# GPMC register map
Vendor: Texas Instruments
Peripheral module from a debugger description file (folder omap5430_ES2_PUBLIC).
Registers are 32-bit, read-write, reset 0x0 unless marked. A register's access mark holds for its fields unless they carry their own. Offsets are as the file gives them; lines under a group give offsets from that group; [hi:lo] are bit positions; {n}, {i} and the like mark numbered series; 'fields as' and 'values as' point back to an identical list; <NAME> marks a mode.

## GPMC
0x00 GPMC_REVISION ro reset not defined — This register contains the IP revision code.
  [31:0] REVISION — IP revision
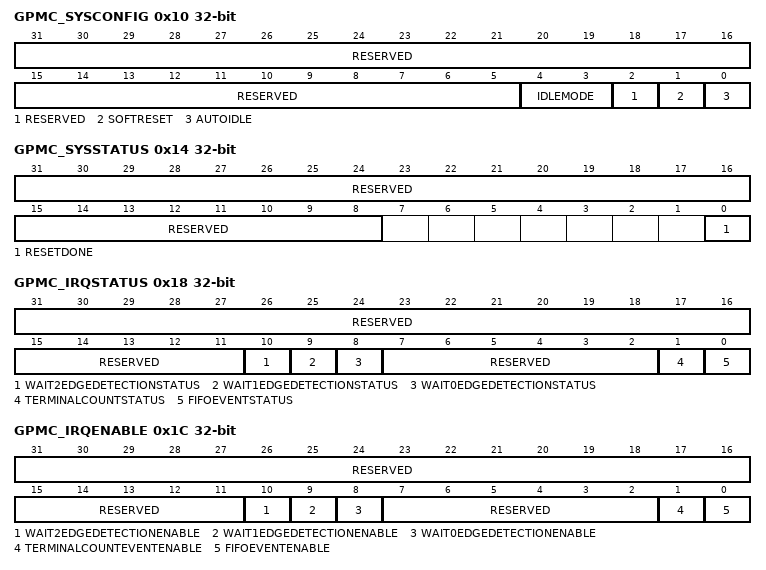
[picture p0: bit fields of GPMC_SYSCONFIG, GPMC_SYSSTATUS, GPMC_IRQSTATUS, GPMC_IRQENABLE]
0x10 GPMC_SYSCONFIG — This register controls the various parameters of the interconnect.
  [31:5] RESERVED — Write 0s for future compatibility. Read returns 0.
  [4:3] IDLEMODE — 0x0: Force-idle. An idle request is acknowledged unconditionally.
    1=No-idle. An idle request is never acknowledged.; 2=Smart-idle. Acknowledgment to an idle request is given based on the internal activity of the module.; 3=Reserved (Do not use.)
  [2] RESERVED — Write 0 for future compatibility Read returns 0.
  [1] SOFTRESET — Software reset. Set this bit to 1 triggers a module reset. This bit is automatically reset by hardware. During reads, it always returns 0.
    0=Normal mode; 1=Reset (The module is reset.)
  [0] AUTOIDLE — Internal interface clock-gating strategy
    0=FreeRun (Interface clock is free-running.); 1=AutoRun (Automatic Interface clock gating strategy is applied, based on the interconnect activity.)
0x14 GPMC_SYSSTATUS ro (reset mask 0xFFFFFFFE) — This register provides status information about the module, excluding the interrupt status information.
  [31:8] RESERVED — Read returns 0.
  [0] RESETDONE — Internal reset monitoring
    0=RstOnGoing (Internal module reset is ongoing.); 1=RstDone (Reset is complete.)
0x18 GPMC_IRQSTATUS — This interrupt status register regroups all the status of the module internal events that can generate an interrupt.
  [31:11] RESERVED — Write 0s for future compatibility. Read returns 0s.
  [10] WAIT2EDGEDETECTIONSTATUS — Status of the Wait2 Edge Detection interrupt
    0=W2Det0_R (A transition on WAIT2 input pin has not been detected.); 0=W2Det0_R (WAIT2EDGEDETECTIONSTATUS bit is unchanged.); 1=W2Det1_R (A transition on WAIT2 input pin has been detected.); 1=W2Det1_R (WAIT2EDGEDETECTIONSTATUS bit is reset.)
  [9] WAIT1EDGEDETECTIONSTATUS — Status of the Wait1 Edge Detection interrupt
    0=W1Det0_R (A transition on WAIT1 input pin has not been detected.); 0=W1Det0_R (WAIT1EDGEDETECTIONSTATUS bit is unchanged.); 1=W1Det1_R (A transition on WAIT1 input pin has been detected.); 1=W1Det1_R (WAIT1EDGEDETECTIONSTATUS bit is reset.)
  [8] WAIT0EDGEDETECTIONSTATUS — Status of the Wait0 Edge Detection interrupt
    0=W0Det0_R (A transition on WAIT0 input pin has not been detected.); 0=W0Det0_R (WAIT0EDGEDETECTIONSTATUS bit is unchanged.); 1=W0Det1_R (A transition on WAIT0 input pin has been detected.); 1=W0Det1_R (WAIT0EDGEDETECTIONSTATUS bit is reset.)
  [7:2] RESERVED — Write 0s for future compatibility. Read returns 0s.
  [1] TERMINALCOUNTSTATUS — Status of the TerminalCountEvent interrupt
    0=TCStat0_R (Indicates that CountValue is greater than 0); 0=TCStat0_R (TERMINALCOUNTSTATUS bit is unchanged.); 1=TCStat1_R (Indicates that CountValue is equal to 0); 1=TCStat1_R (TERMINALCOUNTSTATUS bit is reset.)
  [0] FIFOEVENTSTATUS — Status of the FIFOEvent interrupt
    0=FIFOStat0_R (Indicates that less than[16] FIFOTHRESHOLDSTATUS bytes are available in prefetch mode and less than FIFOTHRESHOLD bytes free places are available in write-posting mode); 0=FIFOStat0_R (FIFOEVENTSTATUS bit is unchanged.); 1=FIFOStat1_R (Indicates that at least[16] FIFOTHRESHOLDSTATUS bytes are available in prefetch mode and at least FIFOTHRESHOLD bytes free places are available in write-posting mode); 1=FIFOStat1_R (FIFOEVENTSTATUS bit is reset.)
0x1C GPMC_IRQENABLE — The interrupt enable register allows to mask/unmask the module internal sources of interrupt, on a event-by-event basis.
  [31:11] RESERVED — Write 0s for future compatibility. Read returns 0s.
  [10] WAIT2EDGEDETECTIONENABLE — Enables the Wait2 Edge Detection interrupt
    0=W2Masked (Wait2EdgeDetection interrupt is masked.); 1=W2Enabled (Wait2EdgeDetection event generates an interrupt if occurs.)
  [9] WAIT1EDGEDETECTIONENABLE — Enables the Wait1 Edge Detection interrupt
    0=W1Masked (Wait1EdgeDetection interrupt is masked.); 1=W1Enabled (Wait1EdgeDetection event generates an interrupt if occurs.)
  [8] WAIT0EDGEDETECTIONENABLE — Enables the Wait0 Edge Detection interrupt
    0=W0Masked (Wait0EdgeDetection interrupt is masked.); 1=W0Enabled (Wait0EdgeDetection event generates an interrupt if occurs.)
  [7:2] RESERVED — Write 0s for future compatibility. Read returns 0s.
  [1] TERMINALCOUNTEVENTENABLE — Enables TerminalCountEvent interrupt issuing in prefetch or write-posting mode
    0=TCMasked (TerminalCountEvent interrupt is masked.); 1=TCEnabled (TerminalCountEvent interrupt is not masked.)
  [0] FIFOEVENTENABLE — Enables the FIFOEvent interrupt
    0=FIFOMasked (FIFOEvent interrupt is masked.); 1=FIFOEnabled (FIFOEvent interrupt is not masked.)
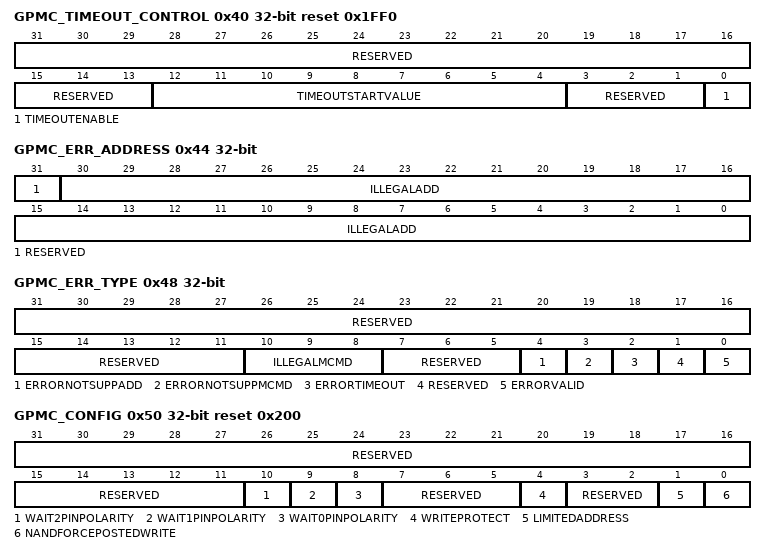
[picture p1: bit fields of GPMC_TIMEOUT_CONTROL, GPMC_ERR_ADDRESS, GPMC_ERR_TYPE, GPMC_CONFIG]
0x40 GPMC_TIMEOUT_CONTROL reset 0x1FF0 — The register allows the user to set the start value of the timeout counter.
  [31:13] RESERVED — Write 0s for future compatibility. Read returns 0s.
  [12:4] TIMEOUTSTARTVALUE — Start value of the time-out counter 0x000: Zero GPMC_FCLK cycle 0x001: One GPMC_FCLK cycle ... 0x1FF: 511 GPMC_FCLK cycles
  [3:1] RESERVED — Write 0s for future compatibility. Read returns 0s.
  [0] TIMEOUTENABLE — Enable bit of the TimeOut feature
    0=TODisabled (TimeOut feature is disabled.); 1=TOEnabled (TimeOut feature is enabled.)
0x44 GPMC_ERR_ADDRESS access per field — The register stores the address of the illegal access when an error occurs.
  [31] RESERVED rw — Write 0s for future compatibility. Read returns 0.
  [30:0] ILLEGALADD ro — Address of illegal access A30: 0 for memory region, 1 for GPMC register region A29-A0: 1 GiB maximum
0x48 GPMC_ERR_TYPE access per field — The register stores the type of error when an error occurs.
  [31:11] RESERVED rw — Write 0s for future compatibility. Read returns 0s.
  [10:8] ILLEGALMCMD ro — System command of the transaction that caused the error
  [7:5] RESERVED rw — Write 0s for future compatibility. Read returns 0s.
  [4] ERRORNOTSUPPADD ro — Not supported address error
    0=No error occurs; 1=Err (The error is due to a nonsupported address.)
  [3] ERRORNOTSUPPMCMD ro — Not supported command error
    0=No error occurs; 1=Err (The error is due to a nonsupported command)
  [2] ERRORTIMEOUT ro — Time-out error
    0=No error occurs; 1=Err (The error is due to a timeout.)
  [1] RESERVED rw — Write 0s for future compatibility. Read returns 0.
  [0] ERRORVALID rw — Error validity status - Must be explicitly cleared with a write 1 transaction
    0=NotValid (All error fields no longer valid); 1=ErrDetect (Error detected and logged in the other error fields)
0x50 GPMC_CONFIG reset 0x200 — The configuration register allows global configuration of the GPMC.
  [31:11] RESERVED — Write 0s for future compatibility. Read returns 0s.
  [10] WAIT2PINPOLARITY — Selects the polarity of input pin WAIT2
    0=W2ActiveL (WAIT2 active low); 1=W2ActiveH (WAIT2 active high)
  [9] WAIT1PINPOLARITY — Selects the polarity of input pin WAIT1
    0=W1ActiveL (WAIT1 active low); 1=W1ActiveH (WAIT1 active high)
  [8] WAIT0PINPOLARITY — Selects the polarity of input pin WAIT0
    0=W0ActiveL (WAIT0 active low); 1=W0ActiveH (WAIT0 active high)
  [7:5] RESERVED — Write 0s for future compatibility. Read returns 0s.
  [4] WRITEPROTECT — Controls the WP output pin level
    0=WPLow (WP output pin is low.); 1=WPHigh (WP output pin is high.)
  [3:2] RESERVED — Write 0s for future compatibility. Read returns 0s.
  [1] LIMITEDADDRESS — Limited Address device support
    0=NoLimited (No effect); 1=Limited (A26-A11 are not modified during an external memory access.)
  [0] NANDFORCEPOSTEDWRITE — Enables the Force Posted Write feature to NAND Cmd/Add/Data location
    0=NoForcePWr (Disables Force Posted Write); 1=ForcePWr (Enables Force Posted Write)
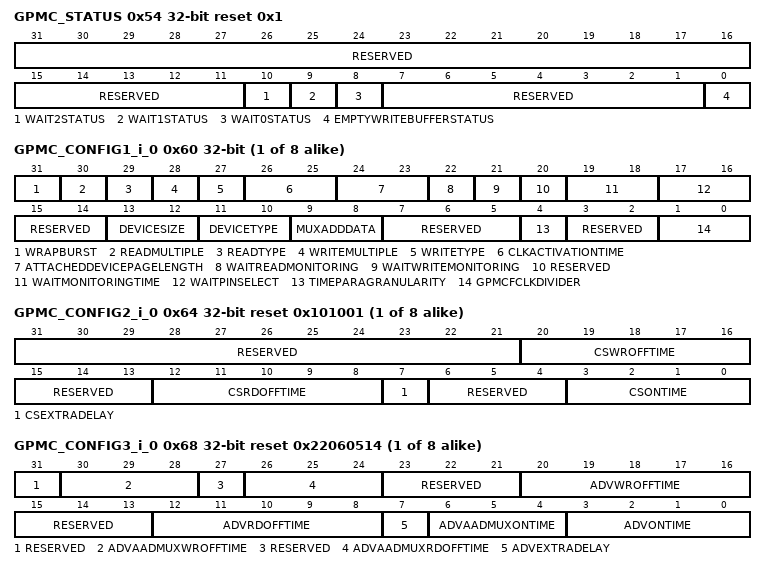
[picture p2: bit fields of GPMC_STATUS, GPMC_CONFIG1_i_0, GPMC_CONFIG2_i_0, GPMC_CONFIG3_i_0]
0x54 GPMC_STATUS access per field reset 0x1 (reset mask 0xFFFFF8FF) — The status register provides global status bits of the GPMC.
  [31:11] RESERVED rw — Write 0s for future compatibility. Read returns 0s.
  [10] WAIT2STATUS ro — Is a copy of input pin WAIT2. (Reset value is WAIT2 input pin sampled at device reset.)
    0=W2ActiveL (WAIT2 asserted (inactive state)); 1=W2ActiveL (WAIT2 deasserted)
  [9] WAIT1STATUS ro — Is a copy of input pin WAIT1. (Reset value is WAIT1 input pin sampled at device reset.)
    0=W1ActiveL (WAIT1 asserted (inactive state)); 1=W1ActiveL (WAIT1 deasserted)
  [8] WAIT0STATUS ro — Is a copy of input pin WAIT0. (Reset value is WAIT0 input pin sampled at device reset.)
    0=W0ActiveL (WAIT0 asserted (inactive state)); 1=W0ActiveL (WAIT0 deasserted)
  [7:1] RESERVED rw — Write 0s for future compatibility. Reads returns 0
  [0] EMPTYWRITEBUFFERSTATUS ro — Stores the empty status of the write buffer
    0=b0 (Write buffer is not empty.); 1=b1 (Write buffer is empty.)
{0x60+0x30*i} GPMC_CONFIG1_i_{i} (reset mask 0xFFBCCCFF) (i=0..7) — The configuration register 1 sets signal control parameters per chip-select.
  [31] WRAPBURST — Enables the wrapping burst capability. Must be set if the attached device is configured in wrapping burst
    0=Synchronous wrapping burst not supported; 1=Synchronous_wrapping_burst_supported
  [30] READMULTIPLE — Selects the read single or multiple access
    0=Single_access; 1=Multiple access (burst if synchronous, page if asynchronous)
  [29] READTYPE — Selects the read mode operation
    0=Read_asynchronous; 1=Read_synchronous
  [28] WRITEMULTIPLE — Selects the write single or multiple access
    0=Single_access; 1=Multiple access (burst if synchronous, considered as single if asynchronous)
  [27] WRITETYPE — Selects the write mode operation
    0=Write_asynchronous; 1=Write_synchronous
  [26:25] CLKACTIVATIONTIME — Output GPMC_CLK activation time
    0=GPMC_CLK_0 (First rising edge of GPMC_CLK at start access time); 1=GPMC_CLK_GPMC_FCLK_1 (First rising edge of GPMC_CLK one GPMC_FCLK cycle after start access time); 2=GPMC_CLK_GPMC_FCLK_2 (First rising edge of GPMC_CLK two GPMC_FCLK cycles after start access time)
  [24:23] ATTACHEDDEVICEPAGELENGTH — Specifies the attached device page (burst) length
    0=4_words; 1=8_words; 2=16_words; 3=Reserved_(1_word_=_interface_size)
  [22] WAITREADMONITORING — Selects the Wait monitoring configuration for Read accesses (Reset value is input pin sampled at device reset)
    0=Wait pin is not monitored for read accesses; 1=Wait pin is monitored for read accesses
  [21] WAITWRITEMONITORING — Selects the Wait monitoring configuration for Write accesses
    0=Wait pin is not monitored for write accesses; 1=Wait pin is monitored for write accesses
  [20] RESERVED — Write 0s for future compatibility. Read returns 0.
  [19:18] WAITMONITORINGTIME — Selects input pin Wait monitoring time
    0=Wait_pin_is_monitored_with_valid_data; 1=GPMC_CLK_1 (Wait pin is monitored one GPMC_CLK cycle before valid data.); 2=GPMC_CLK_2 (Wait pin is monitored two GPMC_CLK cycle before valid data.)
  [17:16] WAITPINSELECT — Selects the input wait pin for this chip-select (Reset value is input pin sampled at device reset for CS0 and 0 for CS1-7)
    0=Wait_input_pin_is_WAIT0; 1=Wait_input_pin_is_WAIT1; 2=Wait_input_pin_is_WAIT2
  [15:14] RESERVED — Write 0s for future compatibility. Reads returns 0
  [13:12] DEVICESIZE — Selects the device size attached (Reset value is input pin sampled at device reset for CS0 and 0x1 for CS1 to CS7)
    0=8_bit; 1=16_bit
  [11:10] DEVICETYPE — Selects the attached device type
    0=NOR_0 (NOR flash-like, asynchronous and synchronous devices); 2=NAND_flash-like_devices,_stream_mode
  [9:8] MUXADDDATA — Enables the address and data multiplexed protocol (Reset value is input pin sampled at device reset for CS0 and 0 for CS1-CS7)
    0=Nonmultiplexed_attached_device; 1=AAD-multiplexed_protocol_device; 2=Address and data multiplexed attached device
  [7:5] RESERVED — Write 0s for future compatibility. Read returns 0s.
  [4] TIMEPARAGRANULARITY — Signals timing latencies scalar factor (RD/WRCYCLETIME, RD/WRACCESSTIME, PAGEBURSTACCESSTIME, CSONTIME, CSRD/WROFFTIME, ADVONTIME, ADVRD/WROFFTIME, OEONTIME, OEOFFTIME, WEONTIME, WEOFFTIME, CYCLE2CYCLEDELAY, BUSTURNAROUND, TIMEOUTSTARTVALUE, WRDATAONADMUXBUS)
    0=x1_latencies; 1=x2_latencies
  [3:2] RESERVED — Write 0s for future compatibility. Read returns 0s.
  [1:0] GPMCFCLKDIVIDER — Divides the GPMC_FCLK clock
    0=GPMC_CLK_GPMC_FCLK_0 (GPMC_CLK frequency = GPMC_FCLK frequency); 1=GPMC_CLK_GPMC_FCLK_1 (GPMC_CLK frequency = GPMC_FCLK frequency / 2); 2=GPMC_CLK_GPMC_FCLK_2 (GPMC_CLK frequency = GPMC_FCLK frequency / 3); 3=GPMC_CLK_GPMC_FCLK_3 (GPMC_CLK frequency = GPMC_FCLK frequency /4)
{0x64+0x30*i} GPMC_CONFIG2_i_{i} reset 0x101001 (i=0..7) — CS signal timing parameter configuration
  [31:21] RESERVED — Write 0s for future compatibility. Read returns 0s.
  [20:16] CSWROFFTIME — CS i deassertion time from start cycle time for write accesses 0x00: 0 GPMC_FCLK cycle 0x01: 1 GPMC_FCLK cycle ... 0x1F: 31 GPMC_FCLK cycles
  [15:13] RESERVED — Write 0s for future compatibility. Read returns 0s.
  [12:8] CSRDOFFTIME — CS i de-assertion time from start cycle time for read accesses 0x00: 0 GPMC_FCLK cycle 0x01: 1 GPMC_FCLK cycle ... 0x1F: 31 GPMC_FCLK cycles
  [7] CSEXTRADELAY — CS i Add extra half-GPMC_FCLK cycle
    0=CS_0 (CS i Timing control signal is not delayed); 1=CS_GPMC_FCLK_1 (CS i Timing control signal is delayed of half GPMC_FCLK clock cycle)
  [6:4] RESERVED — Write 0s for future compatibility. Read returns 0s.
  [3:0] CSONTIME — CS i assertion time from start cycle time 0x0: 0 GPMC_FCLK cycle 0x1: 1 GPMC_FCLK cycle ... 0xF: 15 GPMC_FCLK cycles
{0x68+0x30*i} GPMC_CONFIG3_i_{i} reset 0x22060514 (i=0..7) — nADV signal timing parameter configuration
  [31] RESERVED — Write 0s for future compatibility. Read returns 0s.
  [30:28] ADVAADMUXWROFFTIME — nADV deassertion for first address phase when using the AAD-multiplexed protocol 0x0: 0 GPMC_FCLK cycle 0x1: 1 GPMC_FCLK cycle ... 0x7: 7 GPMC_FCLK cycles
  [27] RESERVED — Write 0s for future compatibility. Read returns 0s.
  [26:24] ADVAADMUXRDOFFTIME — nADV assertion for first address phase when using the AAD-multiplexed protocol 0x0: 0 GPMC_FCLK cycle 0x1: 1 GPMC_FCLK cycle ... 0x7: 7 GPMC_FCLK cycles
  [23:21] RESERVED — Write 0s for future compatibility. Read returns 0s.
  [20:16] ADVWROFFTIME — nADV deassertion time from start cycle time for write accesses 0x00: 0 GPMC_FCLK cycle 0x01: 1 GPMC_FCLK cycle ... 0x1F: 31 GPMC_FCLK cycles
  [15:13] RESERVED — Write 0s for future compatibility. Read returns 0s.
  [12:8] ADVRDOFFTIME — nADV deassertion time from start cycle time for read accesses 0x00: 0 GPMC_FCLK cycle 0x01: 1 GPMC_FCLK cycle ... 0x1F: 31 GPMC_FCLK cycles
  [7] ADVEXTRADELAY — nADV add extra half-GPMC_FCLK cycle
    0=nADV timing control signal is not delayed; 1=GPMC_FCLK_1 (nADV timing control signal is delayed of half GPMC_FCLK clock cycle)
  [6:4] ADVAADMUXONTIME — nADV assertion for first address phase when using the AAD-multiplexed protocol 0x0: 0 GPMC_FCLK cycle 0x1: 1 GPMC_FCLK cycle ... 0x7: 7 GPMC_FCLK cycles
  [3:0] ADVONTIME — nADV assertion time from start cycle time 0x0: 0 GPMC_FCLK cycle 0x1: 1 GPMC_FCLK cycle ... 0xF: 15 GPMC_FCLK cycles
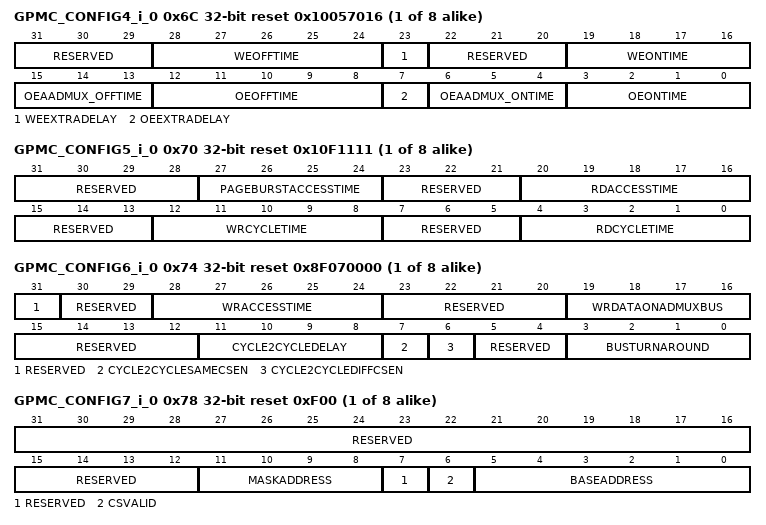
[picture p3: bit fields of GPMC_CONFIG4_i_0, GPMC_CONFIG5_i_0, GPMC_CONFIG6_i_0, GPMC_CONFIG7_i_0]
{0x6C+0x30*i} GPMC_CONFIG4_i_{i} reset 0x10057016 (i=0..7) — nWE and nOE signals timing parameter configuration
  [31:29] RESERVED — Write 0s for future compatibility. Read returns 0s.
  [28:24] WEOFFTIME — nWE deassertion time from start cycle time 0x00: 0 GPMC_FCLK cycle 0x01: 1 GPMC_FCLK cycle ... 0x1F: 31 GPMC_FCLK cycles
  [23] WEEXTRADELAY — nWE add extra half-GPMC_FCLK cycle
    0=nWE timing control signal is not delayed; 1=nWE timing control signal is delayed of half-GPMC_FCLK clock cycle
  [22:20] RESERVED — Write 0s for future compatibility. Read returns 0s.
  [19:16] WEONTIME — nWE assertion time from start cycle time 0x0: 0 GPMC_FCLK cycle 0x1: 1 GPMC_FCLK cycle ... 0xF: 15 GPMC_FCLK cycles
  [15:13] OEAADMUX_OFFTIME — nOE deassertion time for the first address phase in an AAD-multiplexed access 0x0: 0 GPMC_FCLK cycle 0x1: 1 GPMC_FCLK cycle ... 0x7: 7 GPMC_FCLK cycles
  [12:8] OEOFFTIME — nOE deassertion time from start cycle time 0x00: 0 GPMC_FCLK cycle 0x01: 1 GPMC_FCLK cycle ... 0x1F: 31 GPMC_FCLK cycles
  [7] OEEXTRADELAY — nOE add extra half-GPMC_FCLK cycle
    0=nOE timing control signal is not delayed; 1=nOE timing control signal is delayed of half-GPMC_FCLK clock cycle
  [6:4] OEAADMUX_ONTIME — nOE assertion time for the first address phase in an AAD-mux access 0x0: 0 GPMC_FCLK cycle 0x1: 1 GPMC_FCLK cycle ... 0x7: 7 GPMC_FCLK cycles
  [3:0] OEONTIME — nOE assertion time from start cycle time 0x0: 0 GPMC_FCLK cycle 0x1: 1 GPMC_FCLK cycle ... 0xF: 15 GPMC_FCLK cycles
{0x70+0x30*i} GPMC_CONFIG5_i_{i} reset 0x10F1111 (i=0..7) — RdAccessTime and CycleTime timing parameters configuration
  [31:28] RESERVED — Write 0s for future compatibility. Read returns 0s.
  [27:24] PAGEBURSTACCESSTIME — Delay between successive words in a multiple access 0x0: 0 GPMC_FCLK cycle 0x1: 1 GPMC_FCLK cycle ... 0xF: 15 GPMC_FCLK cycles
  [23:21] RESERVED — Write 0s for future compatibility. Read returns 0s.
  [20:16] RDACCESSTIME — Delay between start cycle time and first data valid 0x00: 0 GPMC_FCLK cycle 0x01: 1 GPMC_FCLK cycle ... 0x1F: 31 GPMC_FCLK cycles
  [15:13] RESERVED — Write 0s for future compatibility. Reads returns 0
  [12:8] WRCYCLETIME — Total write cycle time 0x00: 0 GPMC_FCLK cycle 0x01: 1 GPMC_FCLK cycle ... 0x1F: 31 GPMC_FCLK cycles
  [7:5] RESERVED — Write 0s for future compatibility. Read returns 0s.
  [4:0] RDCYCLETIME — Total read cycle time 0x00: 0 GPMC_FCLK cycle 0x01: 1 GPMC_FCLK cycle ... 0x1F: 31 GPMC_FCLK cycles
{0x74+0x30*i} GPMC_CONFIG6_i_{i} reset 0x8F070000 (i=0..7) — WrAccessTime, WrDataOnADmuxBus, Cycle2Cycle and BusTurnAround parameters configuration
  [31] RESERVED — TI Internal use - Do not modify.
  [30:29] RESERVED — Write 0s for future compatibility. Read returns 0s.
  [28:24] WRACCESSTIME — Delay from start access time to the GPMC_FCLK rising edge corresponding the GPMC_CLK rising edge used by the attached memory for the first data capture 0x00: 0 GPMC_FCLK cycle 0x01: 1 GPMC_FCLK cycle ... 0x1F: 31 GPMC_FCLK cycles
  [23:20] RESERVED — Write 0s for future compatibility. Read returns 0s.
  [19:16] WRDATAONADMUXBUS — Specifies on which GPMC_FCLK rising edge the first data of the synchronous burst write is driven in the add/data mux bus
  [15:12] RESERVED — Write 0s for future compatibility. Read returns 0s.
  [11:8] CYCLE2CYCLEDELAY — Chip-select high pulse delay between successive accesses 0x0: 0 GPMC_FCLK cycle 0x1: 1 GPMC_FCLK cycle ... 0xF: 15 GPMC_FCLK cycles
  [7] CYCLE2CYCLESAMECSEN — Add CYCLE2CYCLEDELAY between successive accesses to the same chip-select (any access type)
    0=No_delay_between_the_two_accesses; 1=Add_CYCLE2CYCLEDELAY
  [6] CYCLE2CYCLEDIFFCSEN — Add CYCLE2CYCLEDELAY between successive accesses to a different chip-select (any access type)
    0=No_delay_between_the_two_accesses; 1=Add_CYCLE2CYCLEDELAY
  [5:4] RESERVED — Write 0s for future compatibility. Reads return 0.
  [3:0] BUSTURNAROUND — Bus turnaround latency between successive accesses to the same chip-select (read to write) or to a different chip-select (read to read and read to write) 0x0: 0 GPMC_FCLK cycle 0x1: 1 GPMC_FCLK cycle ... 0xF: 15 GPMC_FCLK cycles
{0x78+0x30*i} GPMC_CONFIG7_i_{i} reset 0xF00 (reset mask 0xFFFFFFBF) (i=0..7) — CS address mapping configuration
  [31:12] RESERVED — Write 0s for future compatibility. Read returns 0s.
  [11:8] MASKADDRESS — CS mask address. 0x1000: Chip-select size of 128 MiB 0x1100: Chip-select size of 64 MiB 0x1110: Chip-select size of 32 MiB 0x1111: Chip-select size of 16 MiB Other values must be avoided as they create holes in the chip-select address space.
  [7] RESERVED — Write 0s for future compatibility. Read returns 0.
  [6] CSVALID — CS enable
    0=CS_disabled; 1=CS_enabled
  [5:0] BASEADDRESS — CSi base address where i = 0 to 7 (16-MiB minimum granularity) bits [5:0] corresponds to A29, A28, A27, A26, A25, and A24. See
{0x7C+0x30*i} GPMC_NAND_COMMAND_i_{i} wo reset not defined (i=0..7) — This register is not a true register, only an address location.
  [31:0] GPMC_NAND_COMMAND — This register is not a true register, only an address location. Writing data at theGPMC_NAND_COMMAND_i location places the data as the NAND command value on the bus, using a regular asynchronous write access.
{0x80+0x30*i} GPMC_NAND_ADDRESS_i_{i} wo reset not defined (i=0..7) — This register is not a true register, only an address location.
  [31:0] GPMC_NAND_ADDRESS — This register is not a true register, only an address location. Writing data at theGPMC_NAND_ADDRESS_i location places the data as the NAND partial address value on the bus, using a regular asynchronous write access.
{0x84+0x30*i} GPMC_NAND_DATA_i_{i} wo reset not defined (i=0..7) — This register is not a true register,only an address location.
  [31:0] GPMC_NAND_DATA — This register is not a true register, only an address location. Reading data from theGPMC_NAND_DATA_i location or from any location in the associated chip-select memory region activates an asynchronous read access.
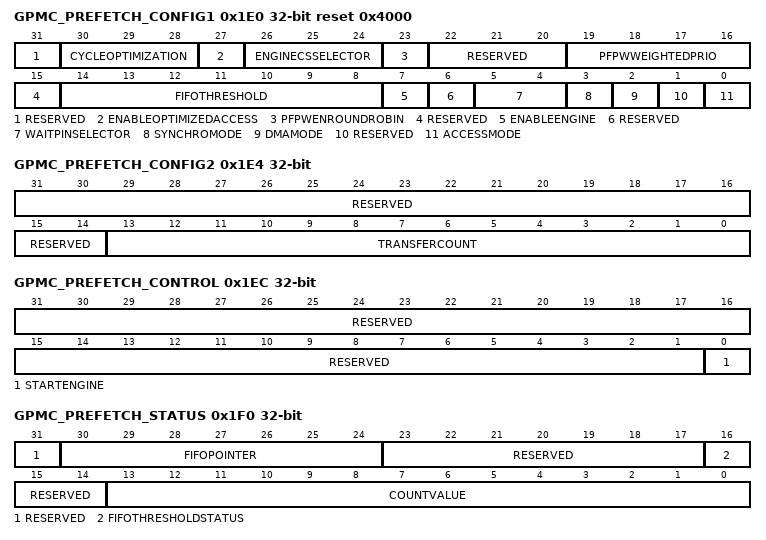
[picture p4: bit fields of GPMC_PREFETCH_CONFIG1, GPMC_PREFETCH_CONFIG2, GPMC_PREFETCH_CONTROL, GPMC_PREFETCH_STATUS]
0x1E0 GPMC_PREFETCH_CONFIG1 reset 0x4000 — Prefetch engine configuration 1
  [31] RESERVED — Write 0s for future compatibility. Read returns 0.
  [30:28] CYCLEOPTIMIZATION — Define the number of GPMC_FCLK cycles to be subtracted from RDCYCLETIME, WRCYCLETIME, ACCESSTIME, CSRDOFFTIME, CSWROFFTIME, ADVRDOFFTIME, ADVWROFFTIME, OEOFFTIME, WEOFFTIME 0x0: 0 GPMC_FCLK cycle 0x1: 1 GPMC_FCLK cycle ... 0x7: 7 GPMC_FCLK cycles
  [27] ENABLEOPTIMIZEDACCESS — Enables access cycle optimization
    0=OptDisabled (Access cycle optimization is disabled.); 1=OptEnabled (Access cycle optimization is enabled.)
  [26:24] ENGINECSSELECTOR — Selects the chip-select where Prefetch Postwrite engine is active 0x0: CS0 0x1: CS1 0x2: CS2 0x3: CS3 0x4: CS4 0x5: CS5 0x6: CS6 0x7: CS7
  [23] PFPWENROUNDROBIN — Enables the PFPW RoundRobin arbitration
    0=RRDisabled (Prefetch Postwrite engine round robin arbitration is disabled.); 1=RREnabled (Prefetch Postwrite engine round robin arbitration is enabled.)
  [22:20] RESERVED — Write 0s for future compatibility. Read returns 0s.
  [19:16] PFPWWEIGHTEDPRIO — When an arbitration occurs between a DMA and a PFPW engine access, the DMA is always serviced. If the PFPWEnRoundRobin is enabled, 0x0: The next access is granted to the PFPW engine. 0x1: The next two accesses are granted to the PFPW engine. ..., 0xF: The next 16 accesses are granted to the PFPW engine.
  [15] RESERVED — Write 0s for future compatibility. Read returns 0.
  [14:8] FIFOTHRESHOLD — Selects the maximum number of bytes read from the FIFO or written to the FIFO by the host on a DMA or interrupt request 0x00: 0 byte 0x01: 1 byte ... 0x40: 64 bytes
  [7] ENABLEENGINE — Enables the Prefetch Postwite engine
    0=PPDisabled (Prefetch Postwrite engine is disabled.); 1=PPEnabled (Prefetch Postwrite engine is enabled.)
  [6] RESERVED — Write 0s for future compatibility. Read returns 0.
  [5:4] WAITPINSELECTOR — Select which wait pin edge detector should start the engine in synchronized mode
    0=W0 (Selects Wait0 EdgeDetection); 1=W1 (Selects Wait1 EdgeDetection); 2=W2 (Selects Wait2 EdgeDetection); 3=W3 (Reserved)
  [3] SYNCHROMODE — Selects when the engine starts the access to chip-select
    0=AtStart (Engine starts the access to chip-select as soon as STARTENGINE is set); 1=AtStartAndWait (Engine starts the access to chip-select as soon as STARTENGINE is set AND wait to nonwait edge detection on the selected wait pin)
  [2] DMAMODE — Selects interrupt synchronization or DMA request synchronization
    0=Interrupt synchronization is enabled. Only interrupt line is activated on FIFO threshold crossing.; 1=DMAReqSync (DMA request synchronization is enabled. A DMA request protocol is used.)
  [1] RESERVED — Write 0s for future compatibility. Read returns 0.
  [0] ACCESSMODE — Selects prefetch read or write-posting accesses
    0=Prefetch read mode; 1=Write-posting mode
0x1E4 GPMC_PREFETCH_CONFIG2 — Prefetch engine configuration 2
  [31:14] RESERVED — Write 0s for future compatibility. Read returns 0s.
  [13:0] TRANSFERCOUNT — Selects the number of bytes to be read or written by the engine to the selected chip-select 0x0000: 0 byte 0x0001: 1 byte ... 0x2000: 8 Kbytes
0x1EC GPMC_PREFETCH_CONTROL — Prefetch engine control
  [31:1] RESERVED — Write 0s for future compatibility. Read returns 0s.
  [0] STARTENGINE — Resets the FIFO pointer and starts the engine
    0=Stop (Engine is stopped.); 0=Stops the engine; 1=Start (Engine is running.); 1=Start (Resets the FIFO pointer to 0x0 in prefetch mode and 0x40 in postwrite mode and starts the engine)
0x1F0 GPMC_PREFETCH_STATUS access per field — Prefetch engine status
  [31] RESERVED rw — Write 0s for future compatibility. Read returns 0.
  [30:24] FIFOPOINTER ro — Number of available bytes to be read or number of free empty byte places to be written 0x00: 0 byte available to be read or 0 free empty place to be written ... 0x40: 64 bytes available to be read or 64 empty places to be written
  [23:17] RESERVED rw — Write 0s for future compatibility. Read returns 0s.
  [16] FIFOTHRESHOLDSTATUS ro — Set when FIFOPointer exceeds FIFOThreshold value
    0=SmallerThanThres (FIFOPointer smaller or equal to FIFOThreshold. Writing to this bit has no effect.); 1=GreaterThanThres (FIFOPointer greater than FIFOThreshold. Writing to this bit has no effect.)
  [15:14] RESERVED rw — Write 0s for future compatibility. Read returns 0s.
  [13:0] COUNTVALUE ro — Number of remaining bytes to be read or to be written by the engine according to the TransferCount value 0x0000: 0 byte remaining to be read or to be written 0x0001: 1 byte remaining to be read or to be written ... 0x2000: 8 KiB remaining to be read or to be written
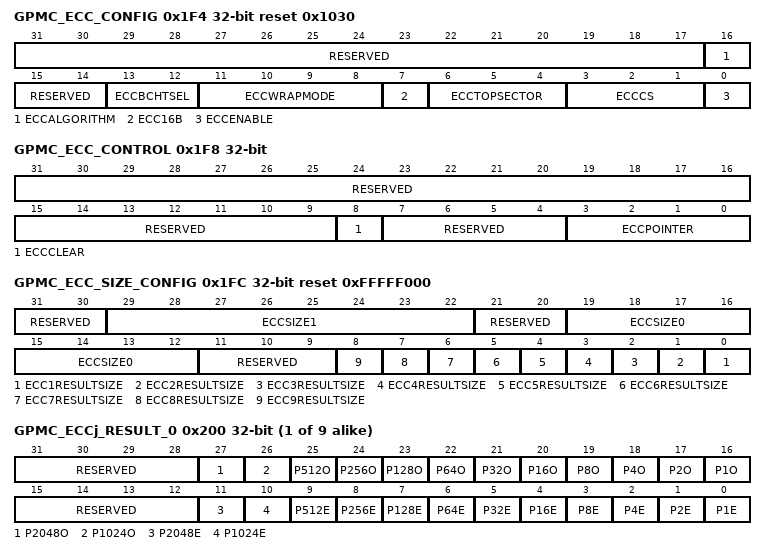
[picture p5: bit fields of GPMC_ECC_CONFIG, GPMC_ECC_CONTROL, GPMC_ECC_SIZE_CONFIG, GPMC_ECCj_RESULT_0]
0x1F4 GPMC_ECC_CONFIG reset 0x1030 — ECC configuration
  [31:17] RESERVED — Write 0s for future compatibility. Read returns 0s.
  [16] ECCALGORITHM — ECC algorithm used
    0=Hamming_code; 1=BCH_code
  [15:14] RESERVED — Write 0s for future compatibility. Read returns 0s.
  [13:12] ECCBCHTSEL — Error correction capability used for BCH
    0=Up_to_4_bits_error_correction_(t_=_4); 1=Up_to_8_bits_error_correction_(t_=_8); 2=Up_to_16_bits_error_correction_(t_=_16)
  [11:8] ECCWRAPMODE — Spare area organization definition for the BCH algorithm. See the BCH syndrome/parity calculator module functional specification for more details
  [7] ECC16B — Selects an ECC calculated on 16 columns
    0=EightCol (ECC calculated on 8 columns); 1=SixteenCol (ECC calculated on 16 columns)
  [6:4] ECCTOPSECTOR — Number of sectors to process with the BCH algorithm 0x0: 1 sector (512-kB page) 0x1: 2 sectors ... 0x3: 4 sectors (2-kB page) ... 0x7: 8 sectors (4-kB page)
  [3:1] ECCCS — Selects the CS where ECC is computedOther: Reserved enum=CS3 .
    {v}=CS{v} (v=0..3)
  [0] ECCENABLE — Enables the ECC feature
    0=ECCDisabled; 1=ECCEnabled
0x1F8 GPMC_ECC_CONTROL — ECC control
  [31:9] RESERVED — Write 0s for future compatibility. Read returns 0s.
  [8] ECCCLEAR — Clear all ECC result registers Reads return 0. Write 0x1 to this field clears all ECC result registers. Write 0x0 is ignored.
  [7:4] RESERVED — Write 0s for future compatibility. Read returns 0s.
  [3:0] ECCPOINTER — Selects ECC result register (Reads to this field give the dynamic position of the ECC pointer - Writes to this field select the ECC result register where the first ECC computation will be stored.); Other enums: writing other values disables the ECC engine (ECCENABLE bit ofGPMC_ECC_CONFIG set to 0)
    0=NoEffect1 (Writing 0x0 disables the ECC engine (ECCENABLE bit of set to 0)); {v}=ECCRes{v} (ECC result register {v} selected) (v=1..9)
0x1FC GPMC_ECC_SIZE_CONFIG reset 0xFFFFF000 — ECC size
  [31:30] RESERVED — Write 0s for future compatibility. Read returns 3.
  [29:22] ECCSIZE1 — Defines Hamming code ECC size 1 in bytes 0x00: 2 bytes 0x01: 4 bytes 0x02: 6 bytes 0x03: 8 bytes ... 0xFF: 512 bytes For BCH code ECC, the size 1 is programmed directly with the number of nibbles. For details, see , .
  [21:20] RESERVED — Write 0s for future compatibility. Read returns 3.
  [19:12] ECCSIZE0 — Defines Hamming code ECC size 0 in bytes 0x00: 2 bytes 0x01: 4 bytes 0x02: 6 bytes 0x03: 8 bytes ... 0xFF: 512 bytes For BCH code ECC, the size 0 is programmed directly with the number of nibbles. For details, see , .
  [11:9] RESERVED — Write 0s for future compatibility. Read returns 0s.
  [n-1] ECC{n}RESULTSIZE (n=1..9) — Selects ECC size for ECC {n} result register
    0=Size0Sel (ECCSIZE0 selected); 1=Size1Sel (ECCSIZE1 selected)
{0x200+4i} GPMC_ECCj_RESULT_{i} access per field (i=0..8) — ECC result register
  [31:28] RESERVED rw — Write 0s for future compatibility. Read returns 0s.
  [27] P2048O ro — Odd row parity bit 2048, only used for ECC computed on 512 bytes
  [26] P1024O ro — Odd row parity bit 1024
  [25] P512O ro — Odd row parity bit 512
  [24] P256O ro — Odd row parity bit 256
  [23] P128O ro — Odd row parity bit 128
  [22] P64O ro — Odd row parity bit 64
  [21] P32O ro — Odd row parity bit 32
  [20] P16O ro — Odd row parity bit 16
  [19] P8O ro — Odd row parity bit 8
  [18] P4O ro — Odd Column Parity bit 4
  [17] P2O ro — Odd Column Parity bit 2
  [16] P1O ro — Odd Column Parity bit 1
  [15:12] RESERVED rw — Write 0s for future compatibility. Read returns 0s.
  [11] P2048E ro — Even row parity bit 2048, only used for ECC computed on 512 bytes
  [10] P1024E ro — Even row parity bit 1024
  [9] P512E ro — Even row parity bit 512
  [8] P256E ro — Even row parity bit 256
  [7] P128E ro — Even row parity bit 128
  [6] P64E ro — Even row parity bit 64
  [5] P32E ro — Even row parity bit 32
  [4] P16E ro — Even row parity bit 16
  [3] P8E ro — Even row parity bit 8
  [2] P4E ro — Even column parity bit 4
  [1] P2E ro — Even column parity bit 2
  [0] P1E ro — Even column parity bit 1
{0x240+0x10*i} GPMC_BCH_RESULT0_i_{i} (i=0..7) — BCH ECC result (bits 0 to 31)
  [31:0] BCH_RESULT_0
{0x244+0x10*i} GPMC_BCH_RESULT1_i_{i} (i=0..7) — BCH ECC result (bits 32 to 63)
  [31:0] BCH_RESULT_1
{0x248+0x10*i} GPMC_BCH_RESULT2_i_{i} (i=0..7) — BCH ECC result (bits 64 to 95)
  [31:0] BCH_RESULT_2
{0x24C+0x10*i} GPMC_BCH_RESULT3_i_{i} (i=0..7) — BCH ECC result (bits 96 to 127)
  [31:0] BCH_RESULT_3
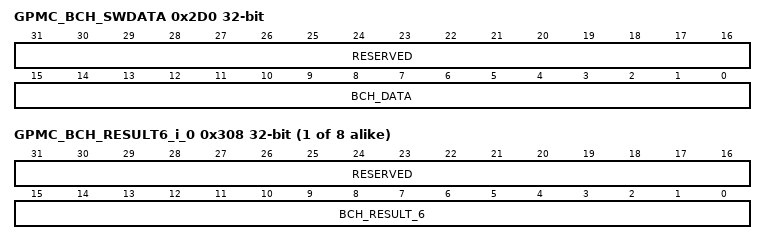
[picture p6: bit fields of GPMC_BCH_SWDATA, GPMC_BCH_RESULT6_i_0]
0x2D0 GPMC_BCH_SWDATA access per field — This register is used to directly pass data to the BCH ECC calculator without accessing the actual NAND flash interface.
  [31:16] RESERVED ro — Write 0s for future compatibility. Read returns 0s.
  [15:0] BCH_DATA rw — Data to be included in the BCH calculation Only bits 0 to 7 are considered if the calculator is configured to use 8-bit data (GPMC_ECC_CONFIG[7] ECC16B = 0)
{0x300+0x10*i} GPMC_BCH_RESULT4_i_{i} (i=0..7) — BCH ECC result (bits 128 to 159)
  [31:0] BCH_RESULT_4
{0x304+0x10*i} GPMC_BCH_RESULT5_i_{i} (i=0..7) — BCH ECC result (bits 160 to 191)
  [31:0] BCH_RESULT_5
{0x308+0x10*i} GPMC_BCH_RESULT6_i_{i} access per field (i=0..7) — BCH ECC result (bits 192 to 207)
  [31:16] RESERVED ro — Write 0s for future compatibility. Read returns 0s.
  [15:0] BCH_RESULT_6 rw — BCH ECC result (bits 192 to 207)
